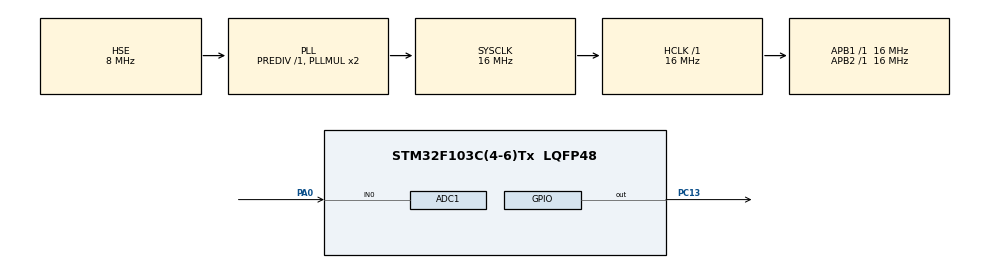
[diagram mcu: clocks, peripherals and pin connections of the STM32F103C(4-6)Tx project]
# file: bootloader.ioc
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ADC1.Channel-0\#ChannelRegularConversion=ADC_CHANNEL_0
ADC1.NbrOfConversionFlag=1
ADC1.Rank-0\#ChannelRegularConversion=1
ADC1.SamplingTime-0\#ChannelRegularConversion=ADC_SAMPLETIME_1CYCLE_5
ADC1.master=1
Mcu.Family=STM32F1
Mcu.Name=STM32F103C(4-6)Tx
Mcu.Package=LQFP48
NVIC.PriorityGroup=NVIC_PRIORITYGROUP_4
PA0-WKUP.Signal=ADCx_IN0
PA13.Mode=Serial_Wire
PA13.Signal=SYS_JTMS-SWDIO
PA14.Mode=Serial_Wire
PA14.Signal=SYS_JTCK-SWCLK
PC13-TAMPER-RTC.Signal=GPIO_Output
PD0-OSC_IN.Mode=HSE-External-Oscillator
PD0-OSC_IN.Signal=RCC_OSC_IN
PD1-OSC_OUT.Mode=HSE-External-Oscillator
PD1-OSC_OUT.Signal=RCC_OSC_OUT
ProjectManager.HeapSize=0x200
ProjectManager.StackSize=0x400
ProjectManager.TargetToolchain=STM32CubeIDE
RCC.AHBFreq_Value=16000000
RCC.APB1Freq_Value=16000000
RCC.APB1TimFreq_Value=16000000
RCC.APB2Freq_Value=16000000
RCC.APB2TimFreq_Value=16000000
RCC.HCLKFreq_Value=16000000
RCC.PLLSourceVirtual=RCC_PLLSOURCE_HSE
RCC.SYSCLKFreq_VALUE=16000000
RCC.SYSCLKSource=RCC_SYSCLKSOURCE_PLLCLK
RCC.USBFreq_Value=16000000
SH.ADCx_IN0.0=ADC1_IN0,IN0
board=custom

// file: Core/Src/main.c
/* USER CODE BEGIN Header */
/**
  ******************************************************************************
  * @file           : main.c
  * @brief          : Main program body
  ******************************************************************************
  * @attention
  *
  * Copyright (c) 2024 STMicroelectronics.
  * All rights reserved.
  *
  * This software is licensed under terms that can be found in the LICENSE file
  * in the root directory of this software component.
  * If no LICENSE file comes with this software, it is provided AS-IS.
  *
  ******************************************************************************
  */
/* USER CODE END Header */
#include "main.h"

/* USER CODE BEGIN Includes */
#include "stm32f1xx_hal_flash.h"
/* USER CODE END Includes */

/* USER CODE BEGIN PTD */
static void goto_application( void );
/* USER CODE END PTD */

/* USER CODE BEGIN PD */
#define APPPLICATION_START_ADDR			0x08004000
#define APPPLICATION_SIZE				0x4000
#define APPPLICATION_RESET_HANDLE_ADDR	APPPLICATION_START_ADDR + 4

#define BK_APPPLICATION_START_ADDR			0x08002000
#define BK_APPPLICATION_SIZE				0x1800

#define INFO_DATA_START_ADDR			BK_APPPLICATION_START_ADDR + BK_APPPLICATION_SIZE
/* USER CODE END PD */

ADC_HandleTypeDef hadc1;

void SystemClock_Config(void);
static void MX_GPIO_Init(void);
static void MX_ADC1_Init(void);

int main(void)
{

  /* MCU Configuration--------------------------------------------------------*/

  /* Reset of all peripherals, Initializes the Flash interface and the Systick. */
  HAL_Init();

  /* Configure the system clock */
  SystemClock_Config();

  /* Initialize all configured peripherals */
  MX_GPIO_Init();
  MX_ADC1_Init();
  /* USER CODE BEGIN 2 */
  HAL_GPIO_WritePin(GPIOC, GPIO_PIN_13, GPIO_PIN_RESET);
  HAL_Delay(1000);
  HAL_GPIO_WritePin(GPIOC, GPIO_PIN_13, GPIO_PIN_SET);
  HAL_Delay(1000);
  HAL_GPIO_WritePin(GPIOC, GPIO_PIN_13, GPIO_PIN_RESET);
  HAL_Delay(1000);
  HAL_GPIO_WritePin(GPIOC, GPIO_PIN_13, GPIO_PIN_SET);
  HAL_Delay(1000);

  uint32_t counter = (uint32_t)(*((volatile uint32_t*) (INFO_DATA_START_ADDR)));

  HAL_FLASH_Unlock();

  counter++;
  counter = ((counter % 3) == 0) ? 0 : counter;

  FLASH_EraseInitTypeDef EraseInitStruct;
  uint32_t PageError;

  EraseInitStruct.TypeErase     = FLASH_TYPEERASE_PAGES;
  EraseInitStruct.Banks 		= FLASH_BANK_1;
  EraseInitStruct.PageAddress	= INFO_DATA_START_ADDR;
  EraseInitStruct.NbPages		= 1;
  HAL_FLASHEx_Erase( &EraseInitStruct, &PageError );

  HAL_FLASH_Program(FLASH_TYPEPROGRAM_WORD, INFO_DATA_START_ADDR, counter);

  HAL_FLASH_Lock();

  counter = (uint32_t)(*((volatile uint32_t*) (INFO_DATA_START_ADDR)));

  if (counter == 2)
  {
	  HAL_FLASH_Unlock();

	  EraseInitStruct.TypeErase     = FLASH_TYPEERASE_PAGES;
	  EraseInitStruct.Banks 		= FLASH_BANK_1;
	  EraseInitStruct.PageAddress	= APPPLICATION_START_ADDR;
	  EraseInitStruct.NbPages		= APPPLICATION_SIZE / 1024;
	  HAL_FLASHEx_Erase( &EraseInitStruct, &PageError );

	  for (uint32_t i = 0; i < BK_APPPLICATION_SIZE; i+=4)
	  {
		  uint32_t data = (uint32_t)(*((volatile uint32_t*) (BK_APPPLICATION_START_ADDR + i)));
		  HAL_FLASH_Program(FLASH_TYPEPROGRAM_WORD, APPPLICATION_START_ADDR + i, data);
	  }

	  HAL_FLASH_Unlock();
  }

  goto_application();

  /* USER CODE END 2 */

  /* Infinite loop */
  while (1)
  {

  }
}

void SystemClock_Config(void)
{
  RCC_OscInitTypeDef RCC_OscInitStruct = {0};
  RCC_ClkInitTypeDef RCC_ClkInitStruct = {0};
  RCC_PeriphCLKInitTypeDef PeriphClkInit = {0};

  /** Initializes the RCC Oscillators according to the specified parameters
  * in the RCC_OscInitTypeDef structure.
  */
  RCC_OscInitStruct.OscillatorType = RCC_OSCILLATORTYPE_HSE;
  RCC_OscInitStruct.HSEState = RCC_HSE_ON;
  RCC_OscInitStruct.HSEPredivValue = RCC_HSE_PREDIV_DIV1;
  RCC_OscInitStruct.HSIState = RCC_HSI_ON;
  RCC_OscInitStruct.PLL.PLLState = RCC_PLL_ON;
  RCC_OscInitStruct.PLL.PLLSource = RCC_PLLSOURCE_HSE;
  RCC_OscInitStruct.PLL.PLLMUL = RCC_PLL_MUL2;
  if (HAL_RCC_OscConfig(&RCC_OscInitStruct) != HAL_OK)
  {
    Error_Handler();
  }

  /** Initializes the CPU, AHB and APB buses clocks
  */
  RCC_ClkInitStruct.ClockType = RCC_CLOCKTYPE_HCLK|RCC_CLOCKTYPE_SYSCLK
                              |RCC_CLOCKTYPE_PCLK1|RCC_CLOCKTYPE_PCLK2;
  RCC_ClkInitStruct.SYSCLKSource = RCC_SYSCLKSOURCE_PLLCLK;
  RCC_ClkInitStruct.AHBCLKDivider = RCC_SYSCLK_DIV1;
  RCC_ClkInitStruct.APB1CLKDivider = RCC_HCLK_DIV1;
  RCC_ClkInitStruct.APB2CLKDivider = RCC_HCLK_DIV1;

  if (HAL_RCC_ClockConfig(&RCC_ClkInitStruct, FLASH_LATENCY_0) != HAL_OK)
  {
    Error_Handler();
  }
  PeriphClkInit.PeriphClockSelection = RCC_PERIPHCLK_ADC;
  PeriphClkInit.AdcClockSelection = RCC_ADCPCLK2_DIV2;
  if (HAL_RCCEx_PeriphCLKConfig(&PeriphClkInit) != HAL_OK)
  {
    Error_Handler();
  }
}

static void MX_ADC1_Init(void)
{

  ADC_ChannelConfTypeDef sConfig = {0};

  /** Common config
  */
  hadc1.Instance = ADC1;
  hadc1.Init.ScanConvMode = ADC_SCAN_DISABLE;
  hadc1.Init.ContinuousConvMode = DISABLE;
  hadc1.Init.DiscontinuousConvMode = DISABLE;
  hadc1.Init.ExternalTrigConv = ADC_SOFTWARE_START;
  hadc1.Init.DataAlign = ADC_DATAALIGN_RIGHT;
  hadc1.Init.NbrOfConversion = 1;
  if (HAL_ADC_Init(&hadc1) != HAL_OK)
  {
    Error_Handler();
  }

  /** Configure Regular Channel
  */
  sConfig.Channel = ADC_CHANNEL_0;
  sConfig.Rank = ADC_REGULAR_RANK_1;
  sConfig.SamplingTime = ADC_SAMPLETIME_1CYCLE_5;
  if (HAL_ADC_ConfigChannel(&hadc1, &sConfig) != HAL_OK)
  {
    Error_Handler();
  }

}

static void MX_GPIO_Init(void)
{
  GPIO_InitTypeDef GPIO_InitStruct = {0};

  /* GPIO Ports Clock Enable */
  __HAL_RCC_GPIOC_CLK_ENABLE();
  __HAL_RCC_GPIOD_CLK_ENABLE();
  __HAL_RCC_GPIOA_CLK_ENABLE();

  /*Configure GPIO pin Output Level */
  HAL_GPIO_WritePin(GPIOC, GPIO_PIN_13, GPIO_PIN_RESET);

  /*Configure GPIO pin : PC13 */
  GPIO_InitStruct.Pin = GPIO_PIN_13;
  GPIO_InitStruct.Mode = GPIO_MODE_OUTPUT_PP;
  GPIO_InitStruct.Pull = GPIO_NOPULL;
  GPIO_InitStruct.Speed = GPIO_SPEED_FREQ_LOW;
  HAL_GPIO_Init(GPIOC, &GPIO_InitStruct);

}

/* USER CODE BEGIN 4 */
static void goto_application(void)
{

  // Turn OFF the Green Led to tell the user that Bootloader is not running
  HAL_GPIO_WritePin(GPIOC, GPIO_PIN_13, GPIO_PIN_SET);
//  __set_MSP(*(volatile uint32_t*) APPPLICATION_START_ADDR);

  /* Jump to application */
  void (*app_reset_handler)(void) = (void*)(*((volatile uint32_t*) (APPPLICATION_RESET_HANDLE_ADDR)));
  app_reset_handler();    //call the app reset handler
}
/* USER CODE END 4 */

void Error_Handler(void)
{
  __disable_irq();
  while (1)
  {
  }
}
